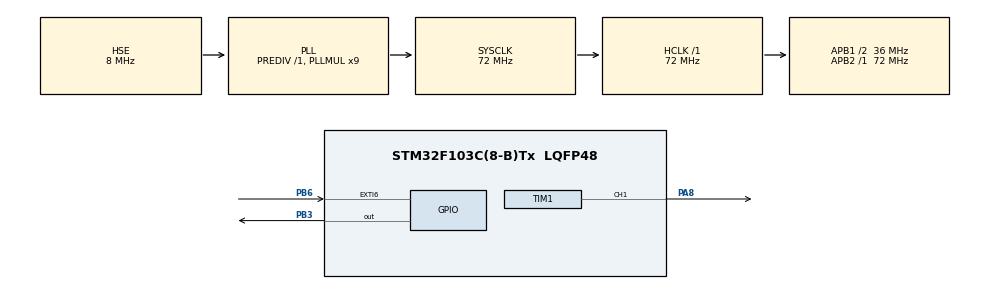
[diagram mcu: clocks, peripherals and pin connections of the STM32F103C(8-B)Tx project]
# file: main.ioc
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Mcu.Family=STM32F1
Mcu.Name=STM32F103C(8-B)Tx
Mcu.Package=LQFP48
NVIC.EXTI9_5_IRQn=true\:0\:0\:false\:false\:true\:true\:true
NVIC.PriorityGroup=NVIC_PRIORITYGROUP_4
PA13.Mode=Serial_Wire
PA13.Signal=SYS_JTMS-SWDIO
PA14.Mode=Serial_Wire
PA14.Signal=SYS_JTCK-SWCLK
PA8.Signal=S_TIM1_CH1
PB3.Signal=GPIO_Output
PB6.GPIO_ModeDefaultEXTI=GPIO_MODE_IT_RISING_FALLING
PB6.Signal=GPXTI6
PC14-OSC32_IN.Mode=LSE-External-Oscillator
PC14-OSC32_IN.Signal=RCC_OSC32_IN
PC15-OSC32_OUT.Mode=LSE-External-Oscillator
PC15-OSC32_OUT.Signal=RCC_OSC32_OUT
PD0-OSC_IN.Mode=HSE-External-Oscillator
PD0-OSC_IN.Signal=RCC_OSC_IN
PD1-OSC_OUT.Mode=HSE-External-Oscillator
PD1-OSC_OUT.Signal=RCC_OSC_OUT
ProjectManager.HeapSize=0x200
ProjectManager.StackSize=0x400
ProjectManager.TargetToolchain=MDK-ARM V5.27
RCC.AHBFreq_Value=72000000
RCC.APB1CLKDivider=RCC_HCLK_DIV2
RCC.APB1Freq_Value=36000000
RCC.APB1TimFreq_Value=72000000
RCC.APB2Freq_Value=72000000
RCC.APB2TimFreq_Value=72000000
RCC.HCLKFreq_Value=72000000
RCC.PLLMUL=RCC_PLL_MUL9
RCC.PLLSourceVirtual=RCC_PLLSOURCE_HSE
RCC.SYSCLKFreq_VALUE=72000000
RCC.SYSCLKSource=RCC_SYSCLKSOURCE_PLLCLK
RCC.USBFreq_Value=72000000
SH.S_TIM1_CH1.0=TIM1_CH1,PWM Generation1 CH1
TIM1.Channel-PWM\ Generation1\ CH1=TIM_CHANNEL_1
TIM1.Period=2000-1
TIM1.Prescaler=720-1
TIM3.Prescaler=72-1
TIM4.Prescaler=72-1
VP_TIM1_VS_ClockSourceINT.Mode=Internal
VP_TIM3_VS_ClockSourceINT.Mode=Internal
VP_TIM4_VS_ClockSourceINT.Mode=Internal
board=custom

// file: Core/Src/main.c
/* USER CODE BEGIN Header */
/**
  ******************************************************************************
  * @file           : main.c
  * @brief          : Main program body - SR04 distance sensor + servo control
  ******************************************************************************
  * @attention
  *
  * <h2><center>&copy; Copyright (c) 2023 STMicroelectronics.
  * All rights reserved.</center></h2>
  *
  * This software component is licensed by ST under BSD 3-Clause license,
  * the "License"; You may not use this file except in compliance with the
  * License. You may obtain a copy of the License at:
  *                        opensource.org/licenses/BSD-3-Clause
  *
  ******************************************************************************
  */
/* USER CODE END Header */
#include "main.h"
#include "tim.h"
#include "gpio.h"

/* USER CODE BEGIN Includes */
#include "driver_sr04.h"  // Custom SR04 ultrasonic driver
/* USER CODE END Includes */

/* USER CODE BEGIN PD */
// Servo angle PWM values (based on calibration)
#define SERVO_NEG90  50
#define SERVO_NEG45  100
#define SERVO_0      150
#define SERVO_45     200
#define SERVO_90     250
/* USER CODE END PD */

/* USER CODE BEGIN PV */
int count = 0;                  // Trigger counter
int distance = 0;               // Last measured distance
uint32_t SR04_tick = 0;         // Timer tick for SR04 trigger
/* USER CODE END PV */

void SystemClock_Config(void);

int main(void)
{

  /* MCU Configuration--------------------------------------------------------*/

  HAL_Init();                         // Reset all peripherals and initialize Flash/Systick
  SystemClock_Config();              // Configure system clock

  MX_GPIO_Init();                    // Initialize GPIOs
  MX_TIM1_Init();                    // Initialize Timer1 (for PWM)
  MX_TIM3_Init();                    // Timer3 (likely for SR04)
  MX_TIM4_Init();                    // Timer4 (used by SR04 for timing echo duration)

  /* USER CODE BEGIN 2 */
  HAL_TIM_PWM_Start(&htim1, TIM_CHANNEL_1);  // Start PWM on TIM1_CH1 for servo motor

  // Servo sweep test on startup
  TIM1->CCR1 = SERVO_NEG90;  // Turn -90°
  HAL_Delay(1000);
  TIM1->CCR1 = SERVO_NEG45;  // Turn -45°
  HAL_Delay(1000);
  TIM1->CCR1 = SERVO_0;      // Center (0°)
  HAL_Delay(1000);
  TIM1->CCR1 = SERVO_45;     // Turn 45°
  HAL_Delay(1000);
  TIM1->CCR1 = SERVO_90;     // Turn 90°
  HAL_Delay(1000);
  /* USER CODE END 2 */

  /* Infinite loop */
  while (1)
  {

    /* USER CODE BEGIN 3 */
    // Trigger SR04 every 50ms
    if (HAL_GetTick() - SR04_tick > 50)
    {
      SR04_tick = HAL_GetTick();   // Update timestamp
      SR04_Tirgger();              // Send trigger pulse to SR04

      // Every 40 triggers (~2s), read distance and update servo
      if (++count == 40)
      {
        count = 0;                     // Reset counter
        distance = GetDistance();     // Get distance in cm

        // If object is closer than 10cm, turn servo to 90°
        if (distance < 10)
        {
          TIM1->CCR1 = SERVO_90;
        }
        else
        {
          TIM1->CCR1 = SERVO_0;       // Else, center the servo
        }
      }
    }
  }
  /* USER CODE END 3 */
}

void SystemClock_Config(void)
{
  RCC_OscInitTypeDef RCC_OscInitStruct = {0};
  RCC_ClkInitTypeDef RCC_ClkInitStruct = {0};

  // Configure oscillator
  RCC_OscInitStruct.OscillatorType = RCC_OSCILLATORTYPE_HSE;
  RCC_OscInitStruct.HSEState = RCC_HSE_ON;
  RCC_OscInitStruct.HSEPredivValue = RCC_HSE_PREDIV_DIV1;
  RCC_OscInitStruct.HSIState = RCC_HSI_ON;
  RCC_OscInitStruct.PLL.PLLState = RCC_PLL_ON;
  RCC_OscInitStruct.PLL.PLLSource = RCC_PLLSOURCE_HSE;
  RCC_OscInitStruct.PLL.PLLMUL = RCC_PLL_MUL9;

  if (HAL_RCC_OscConfig(&RCC_OscInitStruct) != HAL_OK)
  {
    Error_Handler();
  }

  // Configure CPU and bus clocks
  RCC_ClkInitStruct.ClockType = RCC_CLOCKTYPE_HCLK|RCC_CLOCKTYPE_SYSCLK
                              |RCC_CLOCKTYPE_PCLK1|RCC_CLOCKTYPE_PCLK2;
  RCC_ClkInitStruct.SYSCLKSource = RCC_SYSCLKSOURCE_PLLCLK;
  RCC_ClkInitStruct.AHBCLKDivider = RCC_SYSCLK_DIV1;
  RCC_ClkInitStruct.APB1CLKDivider = RCC_HCLK_DIV2;
  RCC_ClkInitStruct.APB2CLKDivider = RCC_HCLK_DIV1;

  if (HAL_RCC_ClockConfig(&RCC_ClkInitStruct, FLASH_LATENCY_2) != HAL_OK)
  {
    Error_Handler();
  }
}

void Error_Handler(void)
{
  /* USER CODE BEGIN Error_Handler_Debug */
  __disable_irq();
  while (1)
  {
    // Trap the processor here in case of fatal error
  }
  /* USER CODE END Error_Handler_Debug */
}

#ifdef  USE_FULL_ASSERT
/**
  * @brief  Reports the name of the source file and the source line number
  *         where the assert_param error has occurred.
  * @param  file: pointer to the source file name
  * @param  line: assert_param error line source number
  * @retval None
  */
void assert_failed(uint8_t *file, uint32_t line)
{
  /* USER CODE BEGIN 6 */
  // Optionally add printf or logging here
  /* USER CODE END 6 */
}
#endif /* USE_FULL_ASSERT */

/************************ (C) COPYRIGHT STMicroelectronics *****END OF FILE****/
